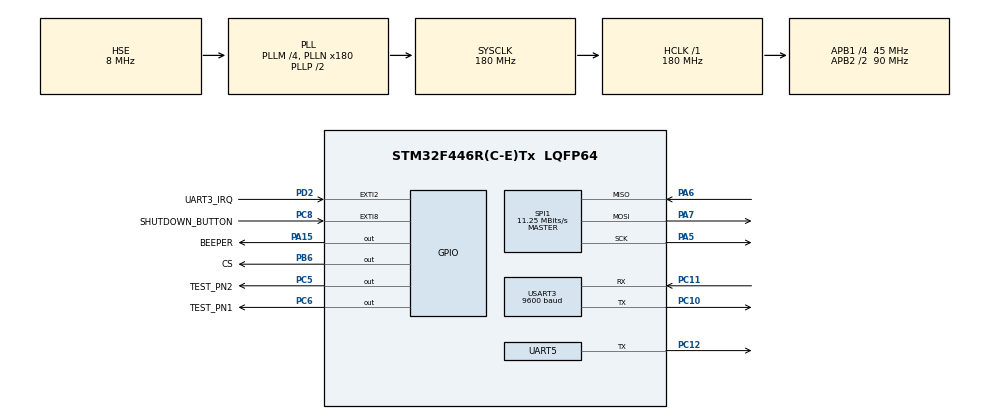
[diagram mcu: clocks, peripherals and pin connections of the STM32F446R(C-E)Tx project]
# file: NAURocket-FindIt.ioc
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Dma.Request0=USART3_RX
Dma.USART3_RX.0.Direction=DMA_PERIPH_TO_MEMORY
Dma.USART3_RX.0.FIFOMode=DMA_FIFOMODE_DISABLE
Dma.USART3_RX.0.Instance=DMA1_Stream1
Dma.USART3_RX.0.MemDataAlignment=DMA_MDATAALIGN_BYTE
Dma.USART3_RX.0.MemInc=DMA_MINC_ENABLE
Dma.USART3_RX.0.Mode=DMA_CIRCULAR
Dma.USART3_RX.0.PeriphDataAlignment=DMA_PDATAALIGN_BYTE
Dma.USART3_RX.0.PeriphInc=DMA_PINC_DISABLE
Dma.USART3_RX.0.Priority=DMA_PRIORITY_LOW
IWDG.Prescaler=IWDG_PRESCALER_64
Mcu.Family=STM32F4
Mcu.Name=STM32F446R(C-E)Tx
Mcu.Package=LQFP64
NVIC.DMA1_Stream1_IRQn=true\:0\:0\:false\:false\:true\:false\:true\:true
NVIC.EXTI2_IRQn=true\:0\:0\:false\:false\:true\:true\:true\:true
NVIC.EXTI9_5_IRQn=true\:0\:0\:false\:false\:true\:true\:true\:true
NVIC.PriorityGroup=NVIC_PRIORITYGROUP_0
NVIC.TIM2_IRQn=true\:0\:0\:false\:false\:true\:true\:true\:true
NVIC.TIM3_IRQn=true\:0\:0\:false\:false\:true\:true\:true\:true
NVIC.TIM4_IRQn=true\:0\:0\:false\:false\:true\:true\:true\:true
PA13.GPIO_Label=TMS
PA13.Mode=Serial_Wire
PA13.Signal=SYS_JTMS-SWDIO
PA14.GPIO_Label=TCK
PA14.Mode=Serial_Wire
PA14.Signal=SYS_JTCK-SWCLK
PA15.GPIO_Label=BEEPER
PA15.GPIO_ModeDefaultOutputPP=GPIO_MODE_OUTPUT_OD
PA15.PinState=GPIO_PIN_SET
PA15.Signal=GPIO_Output
PA5.GPIO_PuPd=GPIO_PULLUP
PA5.Mode=Full_Duplex_Master
PA5.Signal=SPI1_SCK
PA6.GPIO_PuPd=GPIO_PULLUP
PA6.Mode=Full_Duplex_Master
PA6.Signal=SPI1_MISO
PA7.GPIO_PuPd=GPIO_PULLUP
PA7.Mode=Full_Duplex_Master
PA7.Signal=SPI1_MOSI
PB3.GPIO_Label=SWO
PB3.Signal=SYS_JTDO-SWO
PB6.GPIO_Label=CS
PB6.GPIO_PuPd=GPIO_PULLUP
PB6.GPIO_Speed=GPIO_SPEED_FREQ_LOW
PB6.PinState=GPIO_PIN_RESET
PB6.Signal=GPIO_Output
PC10.Mode=Asynchronous
PC10.Signal=USART3_TX
PC11.Mode=Asynchronous
PC11.Signal=USART3_RX
PC12.Mode=Half_duplex(single_wire_mode)
PC12.Signal=UART5_TX
PC5.GPIO_Label=TEST_PN2
PC5.GPIO_PuPd=GPIO_PULLUP
PC5.Signal=GPIO_Output
PC6.GPIO_Label=TEST_PN1
PC6.GPIO_PuPd=GPIO_PULLUP
PC6.Signal=GPIO_Output
PC8.GPIO_Label=SHUTDOWN_BUTTON
PC8.GPIO_ModeDefaultEXTI=GPIO_MODE_IT_RISING_FALLING
PC8.GPIO_PuPd=GPIO_PULLUP
PC8.Signal=GPXTI8
PD2.GPIO_Label=UART3_IRQ
PD2.GPIO_ModeDefaultEXTI=GPIO_MODE_IT_FALLING
PD2.GPIO_PuPd=GPIO_PULLUP
PD2.Signal=GPXTI2
PH0-OSC_IN.Mode=HSE-External-Clock-Source
PH0-OSC_IN.Signal=RCC_OSC_IN
PH1-OSC_OUT.Mode=HSE-External-Clock-Source
PH1-OSC_OUT.Signal=RCC_OSC_OUT
ProjectManager.HeapSize=0x200
ProjectManager.StackSize=0x400
ProjectManager.TargetToolchain=STM32CubeIDE
RCC.48MHZClocksFreq_Value=84000000
RCC.AHBFreq_Value=180000000
RCC.APB1CLKDivider=RCC_HCLK_DIV4
RCC.APB1Freq_Value=45000000
RCC.APB1TimFreq_Value=90000000
RCC.APB2CLKDivider=RCC_HCLK_DIV2
RCC.APB2Freq_Value=90000000
RCC.APB2TimFreq_Value=180000000
RCC.CortexFreq_Value=180000000
RCC.FLatency-AdvancedSettings=FLASH_LATENCY_5
RCC.HCLKFreq_Value=180000000
RCC.HSE_VALUE=8000000
RCC.HSI_VALUE=16000000
RCC.PLLM=4
RCC.PLLN=180
RCC.PLLSourceVirtual=RCC_PLLSOURCE_HSE
RCC.SYSCLKFreq_VALUE=180000000
RCC.SYSCLKSource=RCC_SYSCLKSOURCE_PLLCLK
RCC.USBFreq_Value=180000000
RCC.VCOOutputFreq_Value=360000000
SPI1.BaudRatePrescaler=SPI_BAUDRATEPRESCALER_8
SPI1.CalculateBaudRate=11.25 MBits/s
SPI1.Direction=SPI_DIRECTION_2LINES
SPI1.Mode=SPI_MODE_MASTER
SPI1.VirtualType=VM_MASTER
TIM2.Period=6000-1
TIM2.Prescaler=18000-1
TIM3.CounterMode=TIM_COUNTERMODE_UP
TIM3.Period=2000-1
TIM3.Prescaler=1800-1
TIM4.Period=6000-1
TIM4.Prescaler=18000-1
UART5.Mode=MODE_TX
UART5.VirtualMode=Asynchronous
USART3.BaudRate=9600
USART3.Mode=MODE_TX_RX
USART3.VirtualMode=VM_ASYNC
VP_FATFS_VS_Generic.Mode=User_defined
VP_IWDG_VS_IWDG.Mode=IWDG_Activate
VP_TIM2_VS_ClockSourceINT.Mode=Internal
VP_TIM3_VS_ClockSourceINT.Mode=Internal
VP_TIM4_VS_ClockSourceINT.Mode=Internal
board=NUCLEO-F446RE

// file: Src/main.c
/* USER CODE BEGIN Header */
/**
  ******************************************************************************
  * @file           : main.c
  * @brief          : Main program body
  ******************************************************************************
  * @attention
  *
  * <h2><center>&copy; Copyright (c) 2019 STMicroelectronics.
  * All rights reserved.</center></h2>
  *
  * This software component is licensed by ST under BSD 3-Clause license,
  * the "License"; You may not use this file except in compliance with the
  * License. You may obtain a copy of the License at:
  *                        opensource.org/licenses/BSD-3-Clause
  *
  ******************************************************************************
  */
/* USER CODE END Header */
#include "main.h"
#include "dma.h"
#include "fatfs.h"
#include "iwdg.h"
#include "spi.h"
#include "tim.h"
#include "usart.h"
#include "gpio.h"

/* USER CODE BEGIN Includes */

	#include "NAURocket_FindIt_sm.h"

/* USER CODE END Includes */

void SystemClock_Config(void);

int main(void)
{

  /* MCU Configuration--------------------------------------------------------*/

  /* Reset of all peripherals, Initializes the Flash interface and the Systick. */
  HAL_Init();

  /* Configure the system clock */
  SystemClock_Config();

  /* Initialize all configured peripherals */
  MX_GPIO_Init();
  MX_DMA_Init();
  MX_USART3_UART_Init();
  MX_SPI1_Init();
  MX_FATFS_Init();
  MX_TIM3_Init();
  MX_UART5_Init();
  MX_IWDG_Init();
  MX_TIM4_Init();
  MX_TIM2_Init();
  /* USER CODE BEGIN 2 */

  	  NAUR_Init();

  /* USER CODE END 2 */

  /* Infinite loop */
  /* USER CODE BEGIN WHILE */

  while (1)
  {
	  NAUR_Main();

    /* USER CODE END WHILE */

    /* USER CODE BEGIN 3 */
  }	// end main while
  /* USER CODE END 3 */
}

void SystemClock_Config(void)
{
  RCC_OscInitTypeDef RCC_OscInitStruct = {0};
  RCC_ClkInitTypeDef RCC_ClkInitStruct = {0};

  /** Configure the main internal regulator output voltage
  */
  __HAL_RCC_PWR_CLK_ENABLE();
  __HAL_PWR_VOLTAGESCALING_CONFIG(PWR_REGULATOR_VOLTAGE_SCALE1);

  /** Initializes the RCC Oscillators according to the specified parameters
  * in the RCC_OscInitTypeDef structure.
  */
  RCC_OscInitStruct.OscillatorType = RCC_OSCILLATORTYPE_LSI|RCC_OSCILLATORTYPE_HSE;
  RCC_OscInitStruct.HSEState = RCC_HSE_BYPASS;
  RCC_OscInitStruct.LSIState = RCC_LSI_ON;
  RCC_OscInitStruct.PLL.PLLState = RCC_PLL_ON;
  RCC_OscInitStruct.PLL.PLLSource = RCC_PLLSOURCE_HSE;
  RCC_OscInitStruct.PLL.PLLM = 4;
  RCC_OscInitStruct.PLL.PLLN = 180;
  RCC_OscInitStruct.PLL.PLLP = RCC_PLLP_DIV2;
  RCC_OscInitStruct.PLL.PLLQ = 2;
  RCC_OscInitStruct.PLL.PLLR = 2;
  if (HAL_RCC_OscConfig(&RCC_OscInitStruct) != HAL_OK)
  {
    Error_Handler();
  }

  /** Activate the Over-Drive mode
  */
  if (HAL_PWREx_EnableOverDrive() != HAL_OK)
  {
    Error_Handler();
  }

  /** Initializes the CPU, AHB and APB buses clocks
  */
  RCC_ClkInitStruct.ClockType = RCC_CLOCKTYPE_HCLK|RCC_CLOCKTYPE_SYSCLK
                              |RCC_CLOCKTYPE_PCLK1|RCC_CLOCKTYPE_PCLK2;
  RCC_ClkInitStruct.SYSCLKSource = RCC_SYSCLKSOURCE_PLLCLK;
  RCC_ClkInitStruct.AHBCLKDivider = RCC_SYSCLK_DIV1;
  RCC_ClkInitStruct.APB1CLKDivider = RCC_HCLK_DIV4;
  RCC_ClkInitStruct.APB2CLKDivider = RCC_HCLK_DIV2;

  if (HAL_RCC_ClockConfig(&RCC_ClkInitStruct, FLASH_LATENCY_5) != HAL_OK)
  {
    Error_Handler();
  }
}

void Error_Handler(void)
{
}
